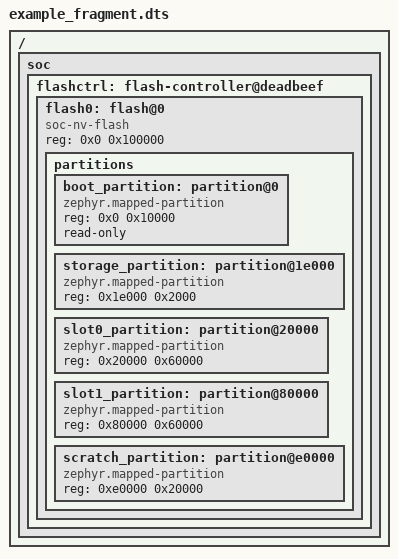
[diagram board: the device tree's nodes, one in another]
/*
 * Copyright (c) 2020-2022 Nordic Semiconductor ASA
 */
/* start-after-here */
/ {
	soc {
		flashctrl: flash-controller@deadbeef {
			flash0: flash@0 {
				compatible = "soc-nv-flash";
				reg = <0x0 0x100000>;
				ranges = <0x0 0x0 0x100000>;

				partitions {
					#address-cells = <1>;
					#size-cells = <1>;
					ranges;

					boot_partition: partition@0 {
						compatible = "zephyr.mapped-partition";
						reg = <0x0 0x10000>;
						read-only;
					};

					storage_partition: partition@1e000 {
						compatible = "zephyr.mapped-partition";
						reg = <0x1e000 0x2000>;
					};

					slot0_partition: partition@20000 {
						compatible = "zephyr.mapped-partition";
						reg = <0x20000 0x60000>;
					};

					slot1_partition: partition@80000 {
						compatible = "zephyr.mapped-partition";
						reg = <0x80000 0x60000>;
					};

					scratch_partition: partition@e0000 {
						compatible = "zephyr.mapped-partition";
						reg = <0xe0000 0x20000>;
					};
				};
			};
		};
	};
};
